# YC3122 register map
Series: ARMCM0; File version: 1.0
CPU: CM0 r1p0, little endian, no MPU, no FPU, 8 interrupt priority bits
Registers are 32-bit, read-write, reset 0x0 unless marked. A register's access mark holds for its fields unless they carry their own. Offsets are from the block's base; [hi:lo] are bit positions; 'fields as' and 'values as' point back to an identical list.

## MLPM
Base 0x000FA800
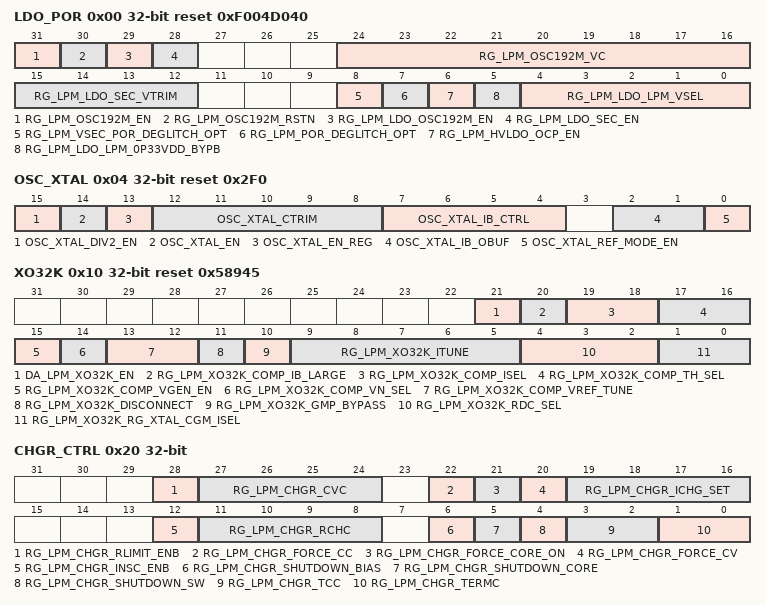
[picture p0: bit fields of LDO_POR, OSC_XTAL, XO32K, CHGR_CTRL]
0x00 LDO_POR reset 0xF004D040 — analog register
  [31] RG_LPM_OSC192M_EN — RC OSC 192MHz enable
  [30] RG_LPM_OSC192M_RSTN — RC OSC 192MHz resetn
  [29] RG_LPM_LDO_OSC192M_EN — RC OSC 192MHz LDO enable
  [28] RG_LPM_LDO_SEC_EN — Security main LDO enable
  [24:16] RG_LPM_OSC192M_VC — RC OSC 192MHz frequency control
  [15:12] RG_LPM_LDO_SEC_VTRIM — Security main LDO output voltage control
  [8] RG_LPM_VSEC_POR_DEGLITCH_OPT — Vlion POR deglitch optimization control, high active
  [7] RG_LPM_POR_DEGLITCH_OPT — Vcoin POR deglitch optimization control, high active
  [6] RG_LPM_HVLDO_OCP_EN — HVLDO over current protection enable
  [5] RG_LPM_LDO_LPM_0P33VDD_BYPB — LPM 0.33vdd ldo bypass to gnd enable control, low active
  [4:0] RG_LPM_LDO_LPM_VSEL — digital aon ldo vout sel
0x04 OSC_XTAL reset 0x2F0 — analog register
  [15] OSC_XTAL_DIV2_EN — xtal to clkpll ref freq div2 enable, high active
  [14] OSC_XTAL_EN — xtal core enable, high active
  [13] OSC_XTAL_EN_REG — xtal regulator enable, high active
  [12:8] OSC_XTAL_CTRIM — xtal cap bank selection
  [7:4] OSC_XTAL_IB_CTRL — xtal core bias current ctrl
  [2:1] OSC_XTAL_IB_OBUF — xtal output buffer bias current ctrl
  [0] OSC_XTAL_REF_MODE_EN — mode cfg
0x10 XO32K reset 0x58945 — XO32K control
  [21] DA_LPM_XO32K_EN — xo32k enable, high active
  [20] RG_LPM_XO32K_COMP_IB_LARGE — xo32k hysteresis comp and current-starved invter bais current enlarge control, high active
  [19:18] RG_LPM_XO32K_COMP_ISEL — xo32k hysteresis comp current selection
  [17:16] RG_LPM_XO32K_COMP_TH_SEL — xo32k hysteresis comp threshold voltage selection, control bits higher, vth higher
  [15] RG_LPM_XO32K_COMP_VGEN_EN — xo32k comp vrefn voltage gen circuit enable, high active
  [14] RG_LPM_XO32K_COMP_VN_SEL — xo32k hysteresis comp negative input signal selection
  [13:12] RG_LPM_XO32K_COMP_VREF_TUNE — xo32k comp voltage selection when vrefn from vgen, control bits higher
  [11] RG_LPM_XO32K_DISCONNECT — disconnect xo32k analog circuit from gpio pad, high active
  [10] RG_LPM_XO32K_GMP_BYPASS — xo32k gm pmos bypass, high active. when xo32k mode
  [9:5] RG_LPM_XO32K_ITUNE — xo32k gm current selection
  [4:2] RG_LPM_XO32K_RDC_SEL — xo32k gm gate-drain dc res type selection
  [1:0] RG_LPM_XO32K_RG_XTAL_CGM_ISEL — xo32k constant-gm current selection
0x20 CHGR_CTRL — CHGR control register
  [28] RG_LPM_CHGR_RLIMIT_ENB — analog register
  [27:24] RG_LPM_CHGR_CVC — analog register
  [22] RG_LPM_CHGR_FORCE_CC — Charger CC mode force enable
  [21] RG_LPM_CHGR_FORCE_CORE_ON — Force on charger CC/CV loop when charger is in standby mode
  [20] RG_LPM_CHGR_FORCE_CV — Charger CV mode force enable
  [19:16] RG_LPM_CHGR_ICHG_SET — Charging current control in CC phase
  [12] RG_LPM_CHGR_INSC_ENB — Charger input sink current enable. Used to wake up charger case and to be turned off upon the end of charging process
  [11:8] RG_LPM_CHGR_RCHC — Battery voltage threshold adjustments for re-charging in 53mV/steps
  [6] RG_LPM_CHGR_SHUTDOWN_BIAS — Force off charger bias
  [5] RG_LPM_CHGR_SHUTDOWN_CORE — Force off charger CC/CV loop
  [4] RG_LPM_CHGR_SHUTDOWN_SW — Force off charger pass transistor
  [3:2] RG_LPM_CHGR_TCC — analog register
  [1:0] RG_LPM_CHGR_TERMC — Charging termination current control
0x200 GPIO_WKEN_W0
  [31:0] LOW — gpio[31:0] 深度睡眠唤醒使能
0x204 GPIO_WKEN_W1
  [31:0] MID — gpio[63:32] 深度睡眠唤醒使能
0x208 GPIO_WKEN_W2
  [15:0] HIGH — gpio[79:64] 深度睡眠唤醒使能
0x210 GPIO_WK_LEVEL
  [0] LEVEL — GPIO唤醒电平设置 0: GPIO高电平唤醒深度睡眠 1: GPIO低电平唤醒深度睡眠
0x214 GPIO_LATCH
  [0] LATCH — nan
0x220 DEEP_SLEEP
  [7:0] EN wo — 写0x5a会进入深度睡眠
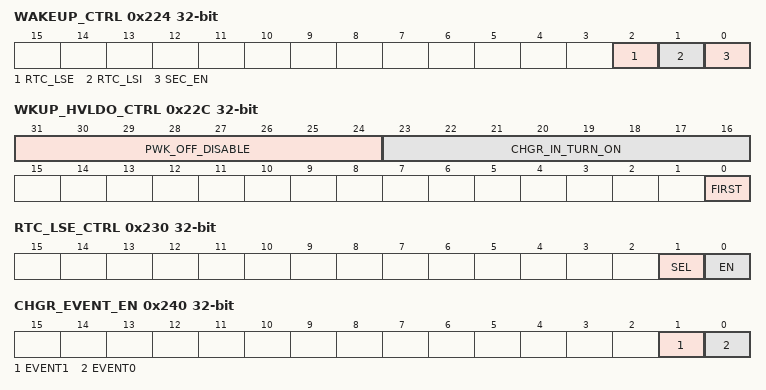
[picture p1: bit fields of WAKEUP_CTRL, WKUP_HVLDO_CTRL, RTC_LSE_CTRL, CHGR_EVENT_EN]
0x224 WAKEUP_CTRL
  [2] RTC_LSE — 1: 使能LSE定时唤醒深度睡眠
  [1] RTC_LSI — 1:使能LSI定时唤醒深度睡眠
  [0] SEC_EN — 1: 使能安全事件唤醒深度睡眠
0x228 WAIT_LDO_CTRL
  [9:0] CNT — core_ldo打开后,等待cnt个osc32k 周期后,开始启动系统,首次上电默认值为32ms deep_sleep时,可通过合理设置此延迟值,减少系统 退出deep_sleep时间
0x22C WKUP_HVLDO_CTRL
  [31:24] PWK_OFF_DISABLE — power key off disable. 0xaa: 禁用power key 关闭系统功能 others: 使能power 关闭系统功能
  [23:16] CHGR_IN_TURN_ON — chgr_in事件打开系统使能 0xaa: 关闭chgr_in事件打开系统功能 others: 打开chgr_in事件打开系统功能
  [0] FIRST — 1: 深度睡眠唤醒时,先打开HVLDO,再进行上 电过程
0x230 RTC_LSE_CTRL
  [1] SEL — RTC_LSE的时钟选择 0: 用LSI作为RTC_LSE的时钟 1:用LSEZ作为RTC_LSE的时钟
  [0] EN — 使能 RTC LSE的时钟
0x240 CHGR_EVENT_EN
  [1] EVENT1 — 1: 使能CHGR_WKUP[11:10]充电标 志位检测和唤醒,使能后需要延时1ms再配置CHGR_WK. UP_HI_EN[11:10]/CHGR_WKUP_LO _EN[11:10]
  [0] EVENT0 — 1: 使能CHGR_WKUP[9:0]充电标志位 检测和唤醒,使能后需要延时1ms再配置CHGR_WKUP _HI_EN[9:0]/CHGR_WKUP_LO_EN[ 9:0]
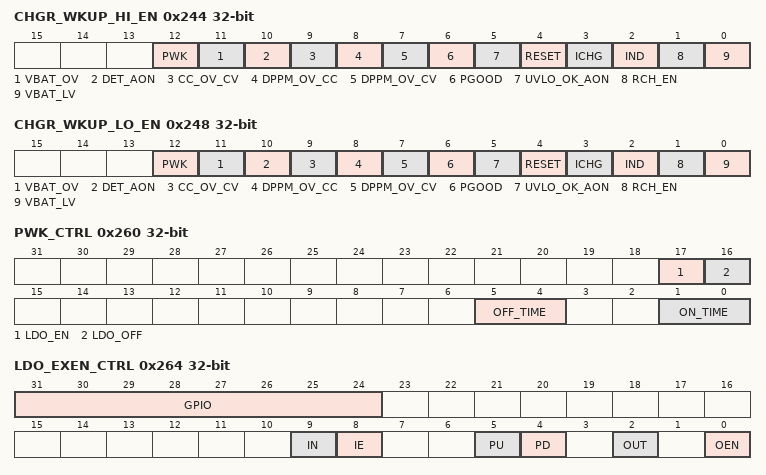
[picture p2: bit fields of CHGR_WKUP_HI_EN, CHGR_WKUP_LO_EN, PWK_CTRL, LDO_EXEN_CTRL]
0x244 CHGR_WKUP_HI_EN
  [12] PWK — power_key
  [11] VBAT_OV — ad_lpm_vbat_ov_flag
  [10] DET_AON — ad_lpm_chgr_in_det_aon
  [9] CC_OV_CV — ad_lpm_chgr_cc_ov_cv
  [8] DPPM_OV_CC — ad_lpm_chgr_dppm_ov_cc
  [7] DPPM_OV_CV — ad_lpm_chgr_dppm_ov_cv
  [6] PGOOD — ad_lpm_chgr_pgood
  [5] UVLO_OK_AON — ad_lpm_chgr_uvlo_ok_aon
  [4] RESET — ad_lpm_chgr_reset
  [3] ICHG — ad_lpm_chgr_state_ichg
  [2] IND — ad_lpm_chgr_state_ind
  [1] RCH_EN — ad_lpm_chgr_state_rch_en
  [0] VBAT_LV — ad_lpm_chgr_state_vbat_l v
0x248 CHGR_WKUP_LO_EN
  fields as CHGR_WKUP_HI_EN
0x260 PWK_CTRL
  [17] LDO_EN wo — 写1 打开HVLDO
  [16] LDO_OFF wo — 写1 关闭HVLDO
  [5:4] OFF_TIME — power_key按下多长时间关闭系统配置 00: 4s. 01: 5s. 10: 6s. 11: 7s
  [1:0] ON_TIME — power key 按下多长时间唤醒系统配置 00: 128ms. 01: 384ms. 10: 640ms. 11: 896ms
0x264 LDO_EXEN_CTRL
  [31:24] GPIO — 0xaa: gpio 模式,pu/pd/ie/o /oen受寄存器控制 others: ldo_exen模式,pu/pd/ie始 终为0,oen为0允许输出,o输出hvldo_en信号
  [9] IN ro — ldo_exen input value
  [8] IE — 0: disable input. 1: enable input
  [5] PU — 1: enable pull-up
  [4] PD — 1: enable pull-down
  [2] OUT — nan
  [0] OEN — 0: enable output. 1: disable output
0x280 CLK_CTRL
  [0] EN — 1: 使能寄存器时钟
0x2A0 ACCESS_CODE
  [7:0] ACCESS_CODE — 按照顺序写入"0x55->0xaa->0x17" 来设置或者清除 "access_en"
0x2A4 ACCESS_EN
  [0] ACCESS_EN — 这1bit 只能在ACCESS_CODE设置后写 入 1: 打开LPM寄存器写入权限 0: 关闭LPM寄存器写入权限 注：每次退出深度睡眠后,access_code和acce ss_en会自动清0,必须重新使能
0x300 BAKEUP_REG0
  [31:0] REG — 复位值是0x5555_5555
0x304 BAKEUP_REG1
  [31:0] REG — 复位值是0xaaaa_aaaa
0x320 BAKEUP_REG2
  [31:0] REG — 无复位功能寄存器
0x324 BAKEUP_REG3
  [31:0] REG — 无复位功能寄存器
